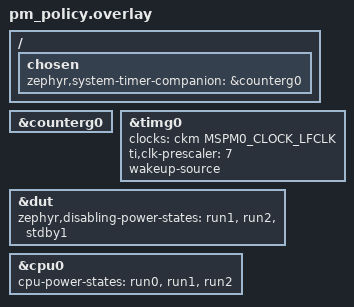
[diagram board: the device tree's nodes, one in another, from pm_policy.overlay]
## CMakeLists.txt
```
# SPDX-License-Identifier: Apache-2.0

cmake_minimum_required(VERSION 3.28.0)
find_package(Zephyr REQUIRED HINTS $ENV{ZEPHYR_BASE})
project(uart_interrupt_api)

target_sources(app PRIVATE
    src/main.c
    )
```

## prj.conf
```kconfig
CONFIG_SERIAL=y
CONFIG_UART_INTERRUPT_DRIVEN=y
CONFIG_UART_USE_RUNTIME_CONFIGURE=y
CONFIG_ZTEST=y
```

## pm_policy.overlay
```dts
/*
 * SPDX-FileCopyrightText: Copyright (c) 2026 Texas Instruments
 * SPDX-License-Identifier: Apache-2.0
 */

/ {
	chosen {
		zephyr,system-timer-companion = &counterg0;
	};
};

&counterg0 {
	status = "okay";
};

&timg0 {
	status = "okay";
	clocks = <&ckm MSPM0_CLOCK_LFCLK>;
	ti,clk-prescaler = <7>;
	wakeup-source;
};

/* UART baud timing requires the RUN0/SLEEP0 ULPCLK frequency. */
&dut {
	zephyr,disabling-power-states = <&run1 &run2 &stdby1>;
};

/* STOP and STANDBY modes are not supported yet. */
&cpu0 {
	cpu-power-states = <&run0 &run1 &run2>;
};
```

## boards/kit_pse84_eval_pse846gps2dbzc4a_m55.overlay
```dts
/*
 * SPDX-FileCopyrightText: Copyright (c) 2026 Infineon Technologies AG,
 * SPDX-FileCopyrightText: or an affiliate of Infineon Technologies AG. All rights reserved.
 *
 * SPDX-License-Identifier: Apache-2.0
 */

dut: &scb5 {
	compatible = "infineon,uart";
	status = "okay";
	current-speed = <115200>;
	clocks = <&peri0_group1_16bit_1>;
	pinctrl-0 = <&p17_1_scb5_uart_tx &p17_0_scb5_uart_rx>;
	pinctrl-names = "default";
};

&gpio_prt17 {
	status = "okay";
};

&p17_1_scb5_uart_tx {
	drive-push-pull;
};

&p17_0_scb5_uart_rx {
	input-enable;
};

&peri0_group1_16bit_1 {
	status = "okay";
	clock-div = <109>;
};
```

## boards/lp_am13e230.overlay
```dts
/*
 * Copyright (c) 2026 Texas Instruments Incorporated
 *
 * SPDX-License-Identifier: Apache-2.0
 */

/* TX (PA2) and RX (PA10) must be connected together for loopback */

&unicomm0 {
	status = "okay";
};

dut: &unicomm0_uart {
	pinctrl-0 = <&uc0_tx_sda_pico_pa2 &uc0_rx_scl_sclk_pa10>;
	pinctrl-names = "default";
	current-speed = <115200>;
	status = "okay";
};
```

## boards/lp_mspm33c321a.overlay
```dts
/*
 * Copyright (c) 2026 Texas Instruments Incorporated
 *
 * SPDX-License-Identifier: Apache-2.0
 */

/* TX (PB12) and RX (PB13) must be connected together for loopback */

&unicomm13_0 {
	status = "okay";
};

dut: &unicomm13_0_uart {
	pinctrl-0 = <&uc13_0_tx_pb12 &uc13_0_rx_pb13>;
	pinctrl-names = "default";
	current-speed = <115200>;
	status = "okay";
};
```

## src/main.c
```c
/*
 * Copyright (c) 2016 Intel Corporation
 * Copyright (c) 2025 Analog Devices, Inc
 *
 * SPDX-License-Identifier: Apache-2.0
 */

#include "test_uart.h"

static volatile bool data_received;
static volatile bool data_transmit_done;
static volatile bool data_receive_done;
static int char_sent;
static int tx_size;
static const char fifo_data[] = "This is a FIFO test.";

#define DATA_SIZE (sizeof(fifo_data))

static void uart_fifo_callback(const struct device *dev, void *user_data)
{
	static int tx_data_idx;
	int ret;

	ARG_UNUSED(user_data);

	/* Verify uart_irq_update() */
	uart_irq_update(dev);

	/* Verify uart_irq_tx_ready() */
	/* Note that TX IRQ may be disabled, but uart_irq_tx_ready() may
	 * still return true when ISR is called for another UART interrupt,
	 * hence additional check for i < DATA_SIZE.
	 */
	if (uart_irq_tx_ready(dev) && tx_data_idx < DATA_SIZE) {
		/* We arrive here by "tx ready" interrupt, so should always
		 * be able to put at least one byte into a FIFO. If not,
		 * well, we'll fail test.
		 */
		tx_size++;
		ret = uart_fifo_fill(dev, (uint8_t *)&fifo_data[tx_data_idx],
				     MIN(tx_size, DATA_SIZE - char_sent));
		if (ret > 0) {
			char_sent += ret;
			tx_data_idx += ret;
		} else {
			TC_PRINT("Failed to fill %d to %s\n", ret, dev->name);
			return;
		}

		if (tx_data_idx == DATA_SIZE) {
			/* If we transmitted everything, stop IRQ stream,
			 * otherwise main app might never run.
			 */
			data_transmit_done = true;
			/* Disable uart_irq_tx after the data transmit is done,
			 * as we don't need any more interrupts.
			 */
			uart_irq_tx_disable(dev);
		}
	}
}

static int test_fifo_tx_sizes(void)
{
	const struct device *const uart_dev = DEVICE_DT_GET(UART_NODE);

	if (!device_is_ready(uart_dev)) {
		TC_PRINT("UART device not ready\n");
		return TC_FAIL;
	}

	char_sent = 0;

	/* Verify uart_irq_callback_set() */
	uart_irq_callback_set(uart_dev, uart_fifo_callback);

	/* Enable Tx/Rx interrupt before using fifo */
	/* Verify uart_irq_tx_enable() */
	uart_irq_tx_enable(uart_dev);

	k_sleep(K_MSEC(500));

	if (!data_transmit_done) {
		return TC_FAIL;
	}

	return TC_PASS;
}

ZTEST(uart_interrupt_api, test_uart_fifo_tx_sizes)
{
#ifndef CONFIG_UART_INTERRUPT_DRIVEN
	ztest_test_skip();
#endif
	zassert_true(test_fifo_tx_sizes() == TC_PASS);
}

ZTEST_SUITE(uart_interrupt_api, NULL, NULL, NULL, NULL, NULL);
```

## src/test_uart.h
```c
/*
 * Copyright (c) 2019 Nordic Semiconductor ASA
 * Copyright (c) 2025 Analog Devices, Inc
 *
 * SPDX-License-Identifier: Apache-2.0
 */

/**
 * @file
 * @brief UART cases header file
 *
 * Header file for UART cases
 */

#ifndef __TEST_UART_H__
#define __TEST_UART_H__

#include <zephyr/drivers/uart.h>
#include <zephyr/ztest.h>

/* RX and TX must not be connected together, to keep TX interrupts isolated */

#if DT_NODE_EXISTS(DT_NODELABEL(dut))
#define UART_NODE DT_NODELABEL(dut)
#else
#define UART_NODE DT_CHOSEN(zephyr_console)
#endif

#endif /* __TEST_UART_H__ */
```
